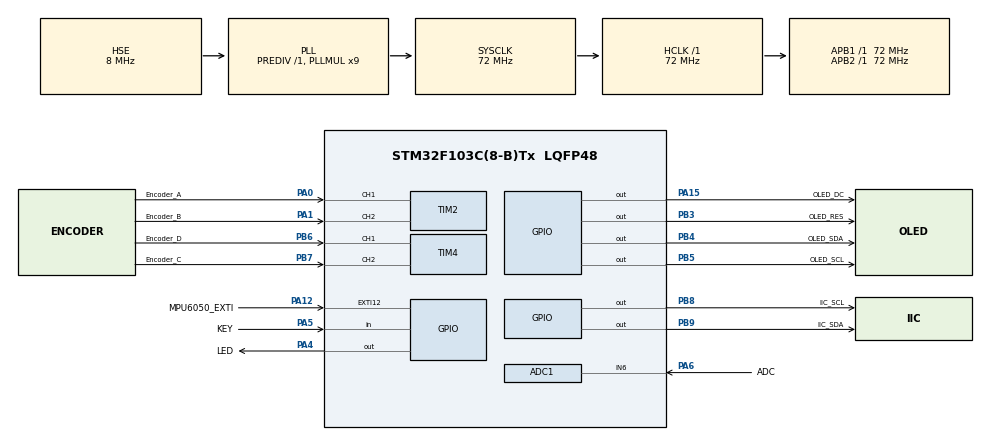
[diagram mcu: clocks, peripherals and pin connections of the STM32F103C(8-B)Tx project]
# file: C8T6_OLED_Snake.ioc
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ADC1.Channel-0\#ChannelRegularConversion=ADC_CHANNEL_6
ADC1.NbrOfConversionFlag=1
ADC1.Rank-0\#ChannelRegularConversion=1
ADC1.SamplingTime-0\#ChannelRegularConversion=ADC_SAMPLETIME_1CYCLE_5
ADC1.master=1
Mcu.Family=STM32F1
Mcu.Name=STM32F103C(8-B)Tx
Mcu.Package=LQFP48
NVIC.EXTI15_10_IRQn=true\:2\:1\:true\:false\:true\:true\:true\:true
NVIC.PriorityGroup=NVIC_PRIORITYGROUP_2
PA0-WKUP.GPIO_Label=Encoder_A
PA0-WKUP.Signal=S_TIM2_CH1_ETR
PA1.GPIO_Label=Encoder_B
PA1.Signal=S_TIM2_CH2
PA12.GPIO_Label=MPU6050_EXTI
PA12.GPIO_PuPd=GPIO_PULLUP
PA12.Signal=GPXTI12
PA13.Mode=Serial_Wire
PA13.Signal=SYS_JTMS-SWDIO
PA14.Mode=Serial_Wire
PA14.Signal=SYS_JTCK-SWCLK
PA15.GPIO_Label=OLED_DC
PA15.GPIO_Speed=GPIO_SPEED_FREQ_MEDIUM
PA15.Signal=GPIO_Output
PA4.GPIO_Label=LED
PA4.PinState=GPIO_PIN_SET
PA4.Signal=GPIO_Output
PA5.GPIO_Label=KEY
PA5.Signal=GPIO_Input
PA6.GPIO_Label=ADC
PA6.Signal=ADCx_IN6
PB3.GPIO_Label=OLED_RES
PB3.GPIO_Speed=GPIO_SPEED_FREQ_HIGH
PB3.Signal=GPIO_Output
PB4.GPIO_Label=OLED_SDA
PB4.GPIO_Speed=GPIO_SPEED_FREQ_MEDIUM
PB4.Signal=GPIO_Output
PB5.GPIO_Label=OLED_SCL
PB5.GPIO_Speed=GPIO_SPEED_FREQ_MEDIUM
PB5.Signal=GPIO_Output
PB6.GPIO_Label=Encoder_D
PB6.Signal=S_TIM4_CH1
PB7.GPIO_Label=Encoder_C
PB7.Signal=S_TIM4_CH2
PB8.GPIO_Label=IIC_SCL
PB8.GPIO_Speed=GPIO_SPEED_FREQ_HIGH
PB8.PinState=GPIO_PIN_SET
PB8.Signal=GPIO_Output
PB9.GPIO_Label=IIC_SDA
PB9.GPIO_Speed=GPIO_SPEED_FREQ_HIGH
PB9.PinState=GPIO_PIN_SET
PB9.Signal=GPIO_Output
PD0-OSC_IN.Mode=HSE-External-Oscillator
PD0-OSC_IN.Signal=RCC_OSC_IN
PD1-OSC_OUT.Mode=HSE-External-Oscillator
PD1-OSC_OUT.Signal=RCC_OSC_OUT
ProjectManager.HeapSize=0x200
ProjectManager.StackSize=0x400
ProjectManager.TargetToolchain=SW4STM32
RCC.AHBFreq_Value=72000000
RCC.APB1Freq_Value=72000000
RCC.APB1TimFreq_Value=72000000
RCC.APB2Freq_Value=72000000
RCC.APB2TimFreq_Value=72000000
RCC.HCLKFreq_Value=72000000
RCC.PLLMUL=RCC_PLL_MUL9
RCC.PLLSourceVirtual=RCC_PLLSOURCE_HSE
RCC.SYSCLKFreq_VALUE=72000000
RCC.SYSCLKSource=RCC_SYSCLKSOURCE_PLLCLK
RCC.USBFreq_Value=72000000
SH.ADCx_IN6.0=ADC1_IN6,IN6
SH.S_TIM2_CH1_ETR.0=TIM2_CH1,Encoder_Interface
SH.S_TIM2_CH2.0=TIM2_CH2,Encoder_Interface
SH.S_TIM4_CH1.0=TIM4_CH1,Encoder_Interface
SH.S_TIM4_CH2.0=TIM4_CH2,Encoder_Interface
TIM2.EncoderMode=TIM_ENCODERMODE_TI12
TIM2.IC1Filter=10
TIM2.IC2Filter=10
TIM4.IC1Filter=10
TIM4.IC2Filter=10
board=custom

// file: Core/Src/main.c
/* USER CODE BEGIN Header */
/**
  ******************************************************************************
  * @file           : main.c
  * @brief          : Main program body
  ******************************************************************************
  * @attention
  *
  * Copyright (c) 2022 STMicroelectronics.
  * All rights reserved.
  *
  * This software is licensed under terms that can be found in the LICENSE file
  * in the root directory of this software component.
  * If no LICENSE file comes with this software, it is provided AS-IS.
  *
  ******************************************************************************
  */
/* USER CODE END Header */
#include "main.h"
#include "adc.h"
#include "tim.h"
#include "gpio.h"

/* USER CODE BEGIN Includes */
#include "oled.h"
#include "snake.h"
#include "encoder.h"
/* USER CODE END Includes */

void SystemClock_Config(void);

int main(void)
{

  /* MCU Configuration--------------------------------------------------------*/

  /* Reset of all peripherals, Initializes the Flash interface and the Systick. */
  HAL_Init();

  /* Configure the system clock */
  SystemClock_Config();

  /* Initialize all configured peripherals */
  MX_GPIO_Init();
  MX_ADC1_Init();
  MX_TIM2_Init();
  MX_TIM4_Init();
  /* USER CODE BEGIN 2 */
  OLED_Init();
  Snake_Display_Init();

  /* USER CODE END 2 */

  /* Infinite loop */
  while (1)
  {
//    Snake_Move_Demo();
    Snake_Move_Encoder(Encoder_Choose(-Read_Encoder(2),-Read_Encoder(4)));
  }
}

void SystemClock_Config(void)
{
  RCC_OscInitTypeDef RCC_OscInitStruct = {0};
  RCC_ClkInitTypeDef RCC_ClkInitStruct = {0};
  RCC_PeriphCLKInitTypeDef PeriphClkInit = {0};

  /** Initializes the RCC Oscillators according to the specified parameters
  * in the RCC_OscInitTypeDef structure.
  */
  RCC_OscInitStruct.OscillatorType = RCC_OSCILLATORTYPE_HSE;
  RCC_OscInitStruct.HSEState = RCC_HSE_ON;
  RCC_OscInitStruct.HSEPredivValue = RCC_HSE_PREDIV_DIV1;
  RCC_OscInitStruct.HSIState = RCC_HSI_ON;
  RCC_OscInitStruct.PLL.PLLState = RCC_PLL_ON;
  RCC_OscInitStruct.PLL.PLLSource = RCC_PLLSOURCE_HSE;
  RCC_OscInitStruct.PLL.PLLMUL = RCC_PLL_MUL9;
  if (HAL_RCC_OscConfig(&RCC_OscInitStruct) != HAL_OK)
  {
    Error_Handler();
  }

  /** Initializes the CPU, AHB and APB buses clocks
  */
  RCC_ClkInitStruct.ClockType = RCC_CLOCKTYPE_HCLK|RCC_CLOCKTYPE_SYSCLK
                              |RCC_CLOCKTYPE_PCLK1|RCC_CLOCKTYPE_PCLK2;
  RCC_ClkInitStruct.SYSCLKSource = RCC_SYSCLKSOURCE_PLLCLK;
  RCC_ClkInitStruct.AHBCLKDivider = RCC_SYSCLK_DIV1;
  RCC_ClkInitStruct.APB1CLKDivider = RCC_HCLK_DIV1;
  RCC_ClkInitStruct.APB2CLKDivider = RCC_HCLK_DIV1;

  if (HAL_RCC_ClockConfig(&RCC_ClkInitStruct, FLASH_LATENCY_2) != HAL_OK)
  {
    Error_Handler();
  }
  PeriphClkInit.PeriphClockSelection = RCC_PERIPHCLK_ADC;
  PeriphClkInit.AdcClockSelection = RCC_ADCPCLK2_DIV2;
  if (HAL_RCCEx_PeriphCLKConfig(&PeriphClkInit) != HAL_OK)
  {
    Error_Handler();
  }
}

void Error_Handler(void)
{
  __disable_irq();
  while (1)
  {
  }
}
